# ISD9300_v3 register map
File version: 1.0
Registers are 32-bit, read-write, reset 0x0 unless marked. A register's access mark holds for its fields unless they carry their own. Offsets are from the block's base; [hi:lo] are bit positions.

## SPI0 — SPI0 Register Map
Base 0x40030000
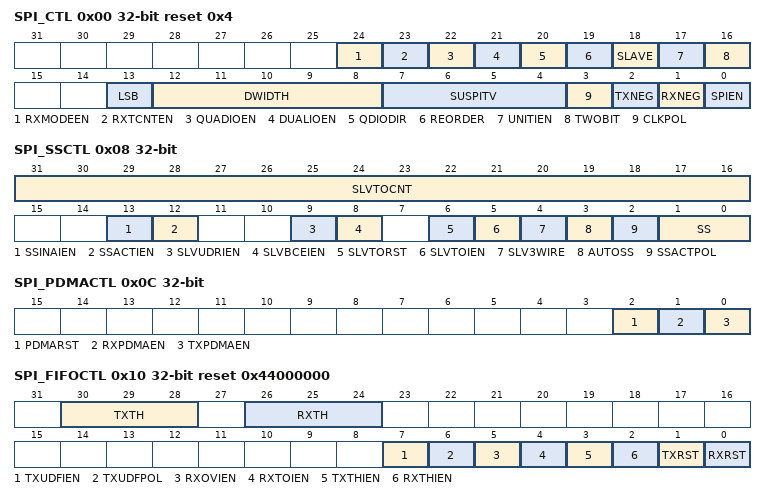
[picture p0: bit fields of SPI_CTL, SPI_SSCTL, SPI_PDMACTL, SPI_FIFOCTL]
0x00 SPI_CTL reset 0x4 — Control and Status Register
  [24] RXMODEEN — FIFO Receive Mode Enable
    0=Disable function; 1=Enable FIFO receive mode. In this mode SPI transactions will be continuously performed while RXFULL is not active. To stop transactions, set RXMODEEN to 0
  [23] RXTCNTEN — DMA Receive Transaction Count Enable
    0=Disable function; 1=Enable transaction counter for DMA receive only mode. SPI will perform the number of transfers specified in the SPI_RXTSNCNT register, allowing the SPI interface to read ahead of DMA controller
  [22] QUADIOEN — Quad I/O Mode Enable
    0=Quad I/O mode Disabled; 1=Quad I/O mode Enabled
  [21] DUALIOEN — Dual I/O Mode Enable
    0=Dual I/O mode Disabled; 1=Dual I/O mode Enabled
  [20] QDIODIR — Quad Or Dual I/O Mode Direction Control
    0=Quad or Dual Input mode; 1=Quad or Dual Output mode
  [19] REORDER — Byte Reorder Function Enable. Note: Byte reorder function is only available if DWIDTH is defined as 16, 24, and 32 bits. REORDER is only available for Receive mode in DUAL and QUAD transactions. For DUAL and QUAD transactions with REORDER, SUSPITV must be set to 0.
    0=Byte reorder function Disabled; 1=Byte reorder function Enabled. A byte suspend interval will be inserted between each byte. The period of the byte suspend interval depends on the setting of SUSPITV
  [18] SLAVE — Master Slave Mode Control
    0=Master mode; 1=Slave mode
  [17] UNITIEN — Unit Transfer Interrupt Enable
    0=Disable SPI Unit Transfer Interrupt; 1=Enable SPI Unit Transfer Interrupt to CPU
  [16] TWOBIT — Two Bits Transfer Mode. When 2-bit mode is enabled, the first serial transmitted bit data is from the first FIFO buffer data, and the 2nd serial transmitted bit data is from the second FIFO buffer data. As the same as transmitted function, the first received bit data is stored into the first FIFO buffer and the 2nd received bit data is stored into the second FIFO buffer at the same time.
    0=Disable two-bit transfer mode; 1=Enable two-bit transfer mode
  [13] LSB — LSB First. Note: For DUAL and QUAD transactions with LSB must be set to 0.
    0=The MSB is transmitted/received first (which bit in TX and RX FIFO depends on the DWIDTH field); 1=The LSB is sent first on the line (bit 0 of TX FIFO]), and the first bit received from the line will be put in the LSB position in the SPIn_RX FIFO (bit 0 SPIn_RX)
  [12:8] DWIDTH — DWIDTH - Data Word Bit Length. This field specifies how many bits are transmitted in one transmit/receive. Up to 32 bits can be transmitted. DWIDTH aaa 0x01 ... 1 bit. DWIDTH aaa 0x02 ... 2 bits ...... DWIDTH aaa 0x1f ... 31 bits. DWIDTH aaa 0x00 ... 32 bits
  [7:4] SUSPITV — Suspend Interval (Master Only). The four bits provide configurable suspend interval between two successive transmit/receive transactions in a transfer. The definition of the suspend interval is the interval between the last clock edge of the preceding transaction word and the first clock edge of the following transaction word. The default value is 0x3. The period of the suspend interval is obtained according to the following equation. SUSPITV is available for standard SPI transactions, it must be set to 0 for DUAL and QUAD mode transactions. (SUSPITV[3:0] + 0.5) * period of SPICLK clock cycle. Example: SUSPITV aaa 0x0 ... 0.5 SPICLK clock cycle. SUSPITV aaa 0x1 ... 1.5 SPICLK clock cycle ...... SUSPITV aaa 0xE ... 14.5 SPICLK clock cycle. SUSPITV aaa 0xF ... 15.5 SPICLK clock cycle. Note: For DUAL and QUAD transactions with SUSPITV must be set to 0.
  [3] CLKPOL — Clock Polarity
    0=SCLK idle low; 1=SCLK idle high
  [2] TXNEG — Transmit At Negative Edge
    0=The transmitted data output signal is changed at the rising edge of SCLK; 1=The transmitted data output signal is changed at the falling edge of SCLK
  [1] RXNEG — Receive At Negative Edge
    0=The received data input signal is latched at the rising edge of SCLK; 1=The received data input signal is latched at the falling edge of SCLK
  [0] SPIEN — SPI Transfer Enable. In Master mode, the transfer will start when there is data in the FIFO buffer after this is set to 1. In Slave mode, the device is ready to receive data when this bit is set to 1. Note: All configuration should be set before writing 1 to this SPIEN bit. (e.g.: TXNEG, RXNEG, DWIDTH, LSB, CLKP, and so on).
    0=Disable SPI Transfer; 1=Enable SPI Transfer
0x04 SPI_CLKDIV — Clock Divider Register (Master Only)
  [7:0] DIVIDER — Clock Divider Register. The value in this field is the frequency divider for generating the SPI engine clock,Fspi_sclk, and the SPI serial clock of SPI master. The frequency is obtained according to the following equation. Fspi_sclk aaa Fspi_clock_src / (DIVIDER+1) where. Fspi_clock_src is the SPI engine clock source, which is defined in the clock control, CLK_SEL1 register.
0x08 SPI_SSCTL — Slave Select Register
  [31:16] SLVTOCNT — Slave Mode Time-Out Period. In Slave mode, these bits indicate the time out period when there is serial clock input during slave select active. The clock source of the time out counter is Slave engine clock. If the value is 0, it indicates the slave mode time-out function is disabled.
  [13] SSINAIEN — Slave Select Inactive Interrupt Enable
    0=Slave select inactive interrupt Disable; 1=Slave select inactive interrupt Enable
  [12] SSACTIEN — Slave Select Active Interrupt Enable
    0=Slave select active interrupt Disable; 1=Slave select active interrupt Enable
  [9] SLVUDRIEN — Slave Mode Error 1 Interrupt Enable
    0=Slave mode error 1 interrupt Disable; 1=Slave mode error 1 interrupt Enable
  [8] SLVBCEIEN — Slave Mode Error 0 Interrupt Enable
    0=Slave mode error 0 interrupt Disable; 1=Slave mode error 0 interrupt Enable
  [6] SLVTORST — Slave Mode Time-Out FIFO Clear
    0=Function disabled; 1=Both the FIFO clear function, TXRST and RXRST, are activated automatically when there is a slave mode time-out event
  [5] SLVTOIEN — Slave Mode Time-Out Interrupt Enable
    0=Slave mode time-out interrupt Disabled; 1=Slave mode time-out interrupt Enabled
  [4] SLV3WIRE — Slave 3-Wire Mode Enable. This is used to ignore the slave select signal in Slave mode. The SPI controller can work with 3-wire interface consisting of SPI_CLK, SPI_MISO, and SPI_MOSI.
    0=4-wire bi-directional interface; 1=3-wire bi-directional interface
  [3] AUTOSS — Automatic Slave Select Function Enable (Master Only)
    0=If this bit is cleared, slave select signals will be asserted/de-asserted by setting/clearing the corresponding bits of SPI_SSCTL[1:0]; 1=If this bit is set, SPI_SS0/1 signals will be generated automatically. It means that device/slave select signal, which is set in SPI_SSCTL[1:0], will be asserted by the SPI controller when transmit/receive is started, and will be de-asserted after each transmit/receive is finished
  [2] SSACTPOL — Slave Select Active Level. This bit defines the active status of slave select signal (SPI_SS0/1).
    0=The slave select signal SPI_SS0/1 is active on low-level/falling-edge; 1=The slave select signal SPI_SS0/1 is active on high-level/rising-edge
  [1:0] SS — Slave Select Control Bits (Master Only). If AUTOSS bit is cleared, writing 1 to any bit of this field sets the proper SPISSx0/1 line to an active state and writing 0 sets the line back to inactive state. If the AUTOSS bit is set, writing 0 to any bit location of this field will keep the corresponding SPI_SS0/1 line at inactive state; writing 1 to any bit location of this field will select appropriate SPI_SS0/1 line to be automatically driven to active state for the duration of the transmit/receive, and will be driven to inactive state for the rest of the time. The active state of SPI_SS0/1 is specified in SSACTPOL. Note: SPI_SS0 is defined as the slave select input in Slave mode.
0x0C SPI_PDMACTL — SPI PDMA Control Register
  [2] PDMARST — PDMA Reset
    0=No effect; 1=Reset the PDMA control logic of the SPI controller. This bit will be cleared to 0 automatically
  [1] RXPDMAEN — Receive PDMA Enable. Setting this bit to 1 will start the receive PDMA process. The SPI controller will issue request to PDMA controller automatically when the SPI receive buffer is not empty. This bit will be cleared to 0 by hardware automatically after PDMA transfer is done.
  [0] TXPDMAEN — Transmit DMA Enable. Setting this bit to 1 will start the transmit PDMA process. SPI controller will issue request to PDMA controller automatically. Hardware will clear this bit to 0 automatically after PDMA transfer done.
0x10 SPI_FIFOCTL reset 0x44000000 — FIFO Control/Status Register
  [30:28] TXTH — Transmit FIFO Threshold. If the valid data count of the transmit FIFO buffer is less than or equal to the TXTH setting, the TXTHIF bit will be set to 1, else the TXTHIF bit will be cleared to 0.
  [26:24] RXTH — Receive FIFO Threshold. If the valid data count of the receive FIFO buffer is larger than the RXTH setting, the RXTHIF bit will be set to 1, else the RXTHIF bit will be cleared to 0.
  [7] TXUDFIEN — Slave Transmit Under Run Interrupt Enable
    0=Slave Transmit FIFO under-run interrupt Disabled; 1=Slave Transmit FIFO under-run interrupt Enabled
  [6] TXUDFPOL — Transmit Under-Run Data Out. Note: The under run event is active after the serial clock input and the hardware synchronous, so that the first 1~3 bit (depending on the relation between system clock and the engine clock) data out will be the last transaction data. Note: If the frequency of system clock approach the engine clock, they may be a 3-bit time to report the transmit under-run data out.
    0=The SPI data out is 0 if there is transmit under-run event in Slave mode; 1=The SPI data out is 1 if there is transmit under-run event in Slave mode
  [5] RXOVIEN — Receive FIFO Overrun Interrupt Enable
    0=Receive FIFO overrun interrupt Disabled; 1=Receive FIFO overrun interrupt Enabled
  [4] RXTOIEN — Slave Receive Time-Out Interrupt Enable
    0=Receive time-out interrupt Disabled; 1=Receive time-out interrupt Enabled
  [3] TXTHIEN — Transmit FIFO Threshold Interrupt Enable
    0=TX FIFO threshold interrupt Disabled; 1=TX FIFO threshold interrupt Enabled
  [2] RXTHIEN — Receive FIFO Threshold Interrupt Enable
    0=RX FIFO threshold interrupt Disabled; 1=RX FIFO threshold interrupt Enabled
  [1] TXRST — Clear Transmit FIFO Buffer. Note: If there is slave receive time out event, the TXRST will be set 1 when the SPI_SSCTL.SLVTORST, is enabled.
    0=No effect; 1=Clear transmit FIFO buffer. The TXFULL bit will be cleared to 0 and the TXEMPTY bit will be set to 1. This bit will be cleared to 0 by hardware about 3 system clocks + 3 SPI engine clock after it is set to 1
  [0] RXRST — Clear Receive FIFO Buffer. Note: If there is slave receive time out event, the RXRST will be set 1 when the SPI_SSCTL.SLVTORST, is enabled.
    0=No effect; 1=Clear receive FIFO buffer. The RXFULL bit will be cleared to 0 and the RXEMPTY bit will be set to 1. This bit will be cleared to 0 by hardware about 3 system clocks + 3 SPI engine clock after it is set to 1
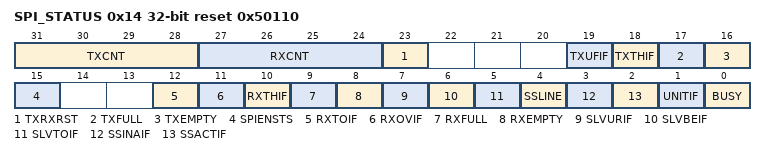
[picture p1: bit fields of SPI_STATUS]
0x14 SPI_STATUS reset 0x50110 — Status Register
  [31:28] TXCNT ro — Transmit FIFO Data Count (Read Only). This bit field indicates the valid data count of transmit FIFO buffer.
  [27:24] RXCNT ro — Receive FIFO Data Count (Read Only). This bit field indicates the valid data count of receive FIFO buffer.
  [23] TXRXRST ro — FIFO CLR Status (Read Only). Note: Both the TXRST, RXRST, need 3 system clock + 3 engine clocks, the status of this bit allows the user to monitor whether the clear function is busy or done.
    0=Done the FIFO buffer clear function of TXRST and RXRST; 1=Doing the FIFO buffer clear function of TXRST or RXRST
  [19] TXUFIF ro — Slave Transmit FIFO Under-Run Interrupt Status (Read Only). When the transmit FIFO buffer is empty and further serial clock pulses occur, data transmitted will be the value of the last transmitted bit and this under-run bit will be set. Note: This bit will be cleared by writing 1 to itself.
  [18] TXTHIF ro — Transmit FIFO Threshold Interrupt Status (Read Only). Note: If TXTHIEN aaa 1 and TXTHIF aaa 1, the SPI controller will generate a SPI interrupt request.
    0=The valid data count of the transmit FIFO buffer is larger than the setting value of TXTH; 1=The valid data count of the transmit FIFO buffer is less than or equal to the setting value of TXTH
  [17] TXFULL ro — Transmit FIFO Buffer Full Indicator (Read Only)
    0=Transmit FIFO buffer is not full; 1=Transmit FIFO buffer is full
  [16] TXEMPTY ro — Transmit FIFO Buffer Empty Indicator (Read Only)
    0=Transmit FIFO buffer is not empty; 1=Transmit FIFO buffer is empty
  [15] SPIENSTS ro — SPI Enable Bit Status (Read Only). Note: The clock source of SPI controller logic is engine clock, it is asynchronous with the system clock. In order to make sure the function is disabled in SPI controller logic, this bit indicates the real status of SPIEN in SPI controller logic for user.
    0=Indicate the transmit control bit is disabled; 1=Indicate the transfer control bit is active
  [12] RXTOIF — Receive Time-Out Interrupt Status. Note: This bit will be cleared by writing 1 to itself.
    0=No receive FIFO time-out event; 1=Receive FIFO buffer is not empty and no read operation on receive FIFO buffer over 64 SPI clock period in Master mode or over 576 SPI engine clock period in Slave mode. When the received FIFO buffer is read by software, the time-out status will be cleared automatically
  [11] RXOVIF — Receive FIFO Overrun Status. When the receive FIFO buffer is full, the follow-up data will be dropped and this bit will be set to 1. Note: This bit will be cleared by writing 1 to itself.
  [10] RXTHIF ro — Receive FIFO Threshold Interrupt Status (Read Only). Note: If RXTHIEN aaa 1 and RXTHIF aaa 1, the SPI controller will generate a SPI interrupt request.
    0=The valid data count within the Rx FIFO buffer is smaller than or equal to the setting value of RXTH; 1=The valid data count within the receive FIFO buffer is larger than the setting value of RXTH
  [9] RXFULL ro — Receive FIFO Buffer Full Indicator (Read Only)
    0=Receive FIFO buffer is not full; 1=Receive FIFO buffer is full
  [8] RXEMPTY ro — Receive FIFO Buffer Empty Indicator (Read Only)
    0=Receive FIFO buffer is not empty; 1=Receive FIFO buffer is empty
  [7] SLVURIF ro — Slave Mode Error 1 Interrupt Status (Read Only). In Slave mode, transmit under-run occurs when the slave select line goes to inactive state.
    0=No Slave mode error 1 event; 1=Slave mode error 1 occurs
  [6] SLVBEIF ro — Slave Mode Error 0 Interrupt Status (Read Only). In Slave mode, there is bit counter mismatch with DWIDTH when the slave select line goes to inactive state. Note: If the slave select active but there is no any serial clock input, the SLVBEIF also active when the slave select goes to inactive state.
    0=No Slave mode error 0 event; 1=Slave mode error 0 occurs
  [5] SLVTOIF ro — Slave Time-Out Interrupt Status (Read Only). When the Slave Select is active and the value of SLVTOCNT is not 0 and the serial clock input, the slave time-out counter in SPI controller logic will be start. When the value of time-out counter greater or equal than the value of SPI_SSCTL.SLVTOCNT, during before one transaction done, the slave time-out interrupt event will active. Note: If the DWIDTH is set 16, one transaction is equal 16 bits serial clock period.
    0=Slave time-out is not active; 1=Slave time-out is active
  [4] SSLINE ro — Slave Select Line Bus Status (Read Only). Note: If SPI_SSCTL.SSACTPOL is set 0, and the SSLINE is 1, the SPI slave select is in inactive status.
    0=Indicates the slave select line bus status is 0; 1=Indicates the slave select line bus status is 1
  [3] SSINAIF — Slave Select Inactive Interrupt Status. Note: This bit will be cleared by writing 1 to itself.
    0=Slave select inactive interrupt is clear or not occur; 1=Slave select inactive interrupt event has occur
  [2] SSACTIF — Slave Select Active Interrupt Status. Note: This bit will be cleared by writing 1 to itself.
    0=Slave select active interrupt is clear or not occur; 1=Slave select active interrupt event has occur
  [1] UNITIF — Unit Transfer Interrupt Status. Note: This bit will be cleared by writing 1 to itself.
    0=No transaction has been finished since this bit was cleared to 0; 1=SPI controller has finished one unit transfer
  [0] BUSY ro — SPI Unit Bus Status (Read Only). The following listing are the bus busy conditions: SPIEN aaa 1 and the TXEMPTY aaa 0. For SPI Master, the TXEMPTY aaa 1 but the current transaction is not finished yet. For SPI Slave receive mode, the SPIEN aaa 1 and there is serial clock input into the SPI core logic when slave select is active. For SPI Slave transmit mode, the SPIEN aaa 1 and the transmit buffer is not empty in SPI core logic event if the slave select is inactive.
    0=No transaction in the SPI bus; 1=SPI controller unit is in busy state
0x18 SPI_RXTSNCNT — Receive Transaction Count Register
  [16:0] RXTSNCNT — DMA Receive Transaction Count. When using DMA to receive SPI data without transmitting data, this register can be used in conjunction with the control bit SPI_CTL.RXTCNTEN to set number of transactions to perform. Without this, the SPI interface will only initiate a transaction when it receives a request from the DMA system, resulting in a lower achievable data rate.
0x20 SPI_TX wo — FIFO Data Transmit Register
  [31:0] TX — Data Transmit Register. A write to the data transmit register pushes data onto into the 8-level transmit FIFO buffer. The number of valid bits depends on the setting of transmit bit width field of the SPI_CTL register. For example, if DWIDTH is set to 0x08, the bits TX[7:0] will be transmitted. If DWIDTH is set to 0, the SPI controller will perform a 32-bit transfer.
0x30 SPI_RX ro — FIFO Data Receive Register
  [31:0] RX — Data Receive Register. A read from this register pops data from the 8-level receive FIFO. Valid data is present if the SPI_STATUS. RXEMPTY bit is not set to 1. This is a read-only register.
